# STM32F3x8 register map
File version: 1.2
CPU: CM4 r0p0, little endian, 4 interrupt priority bits
Registers are 32-bit, read-write, reset 0x0 unless marked. A register's access mark holds for its fields unless they carry their own. Offsets are from the block's base; [hi:lo] are bit positions; {n}, {i} and the like mark numbered series; 'fields as' and 'values as' point back to an identical list.

## DBGMCU — Debug support
Base 0xE0042000
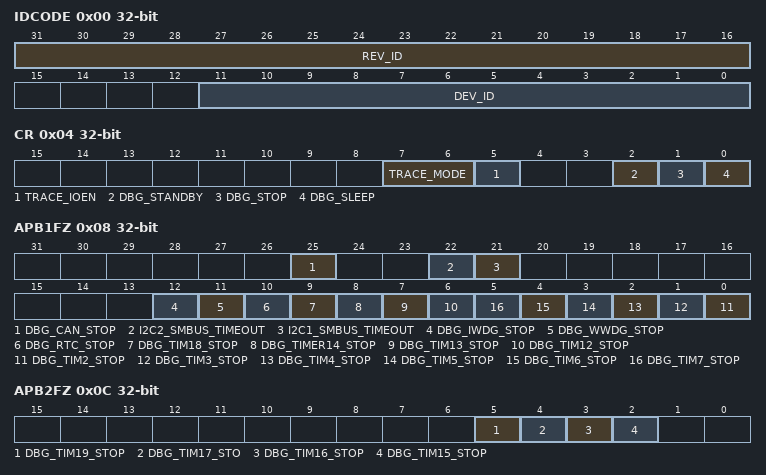
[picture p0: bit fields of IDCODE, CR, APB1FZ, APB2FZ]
0x00 IDCODE ro — MCU Device ID Code Register
  [31:16] REV_ID — Revision Identifier
  [11:0] DEV_ID — Device Identifier
0x04 CR — Debug MCU Configuration Register
  [7:6] TRACE_MODE — Trace pin assignment control
  [5] TRACE_IOEN — Trace pin assignment control
  [2] DBG_STANDBY — Debug Standby Mode
  [1] DBG_STOP — Debug Stop Mode
  [0] DBG_SLEEP — Debug Sleep mode
0x08 APB1FZ — APB Low Freeze Register
  [25] DBG_CAN_STOP — Debug CAN stopped when core is halted
  [22] I2C2_SMBUS_TIMEOUT — SMBUS timeout mode stopped when Core is halted
  [21] I2C1_SMBUS_TIMEOUT — SMBUS timeout mode stopped when Core is halted
  [12] DBG_IWDG_STOP — Debug Independent Wachdog stopped when Core is halted
  [11] DBG_WWDG_STOP — Debug Window Wachdog stopped when Core is halted
  [10] DBG_RTC_STOP — Debug RTC stopped when Core is halted
  [9] DBG_TIM18_STOP — Debug Timer 18 stopped when Core is halted
  [8] DBG_TIMER14_STOP — Debug Timer 14 stopped when Core is halted
  [7] DBG_TIM13_STOP — Debug Timer 13 stopped when Core is halted
  [6] DBG_TIM12_STOP — Debug Timer 12 stopped when Core is halted
  [n-2] DBG_TIM{n}_STOP (n=2..7) — Debug Timer {n} stopped when Core is halted
0x0C APB2FZ — APB High Freeze Register
  [5] DBG_TIM19_STOP — Debug Timer 19 stopped when Core is halted
  [4] DBG_TIM17_STO — Debug Timer 17 stopped when Core is halted
  [3] DBG_TIM16_STOP — Debug Timer 16 stopped when Core is halted
  [2] DBG_TIM15_STOP — Debug Timer 15 stopped when Core is halted

## FMC — Flexible memory controller
Base 0xA0000400
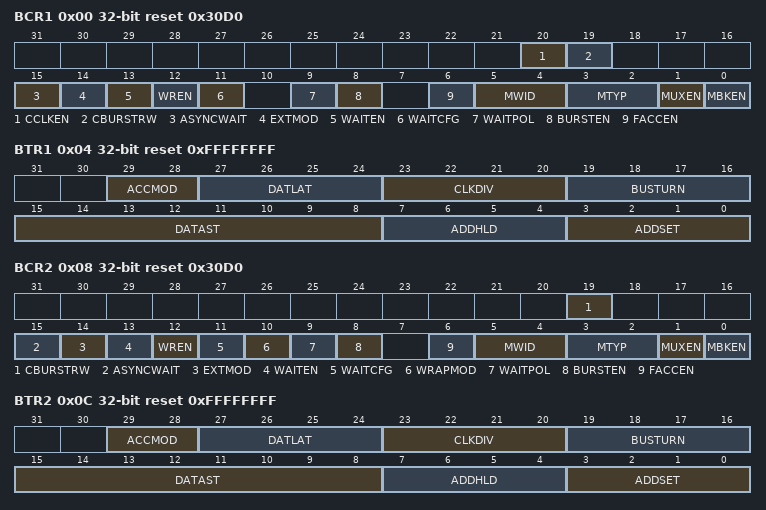
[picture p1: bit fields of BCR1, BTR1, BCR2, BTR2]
0x00 BCR1 reset 0x30D0 — SRAM/NOR-Flash chip-select control register 1
  [20] CCLKEN, [19] CBURSTRW, [15] ASYNCWAIT, [14] EXTMOD, [13] WAITEN, [12] WREN, [11] WAITCFG, [9] WAITPOL, [8] BURSTEN, [6] FACCEN, [5:4] MWID, [3:2] MTYP, [1] MUXEN, [0] MBKEN
0x04 BTR1 reset 0xFFFFFFFF — SRAM/NOR-Flash chip-select timing register 1
  [29:28] ACCMOD, [27:24] DATLAT, [23:20] CLKDIV, [19:16] BUSTURN, [15:8] DATAST, [7:4] ADDHLD, [3:0] ADDSET
0x08 BCR2 reset 0x30D0 — SRAM/NOR-Flash chip-select control register 2
  [19] CBURSTRW, [15] ASYNCWAIT, [14] EXTMOD, [13] WAITEN, [12] WREN, [11] WAITCFG, [10] WRAPMOD, [9] WAITPOL, [8] BURSTEN, [6] FACCEN, [5:4] MWID, [3:2] MTYP, [1] MUXEN, [0] MBKEN
0x0C BTR2 reset 0xFFFFFFFF — SRAM/NOR-Flash chip-select timing register 2
  fields as BTR1
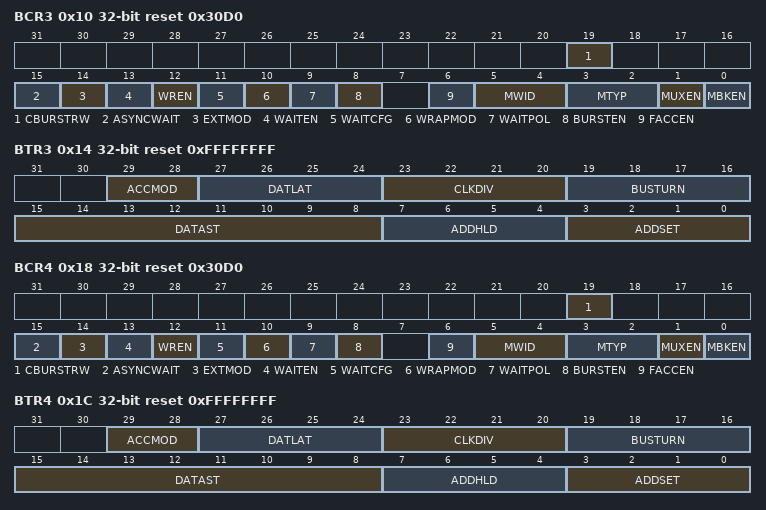
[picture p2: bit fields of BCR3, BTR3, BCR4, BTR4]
0x10 BCR3 reset 0x30D0 — SRAM/NOR-Flash chip-select control register 3
  fields as BCR2
0x14 BTR3 reset 0xFFFFFFFF — SRAM/NOR-Flash chip-select timing register 3
  fields as BTR1
0x18 BCR4 reset 0x30D0 — SRAM/NOR-Flash chip-select control register 4
  fields as BCR2
0x1C BTR4 reset 0xFFFFFFFF — SRAM/NOR-Flash chip-select timing register 4
  fields as BTR1
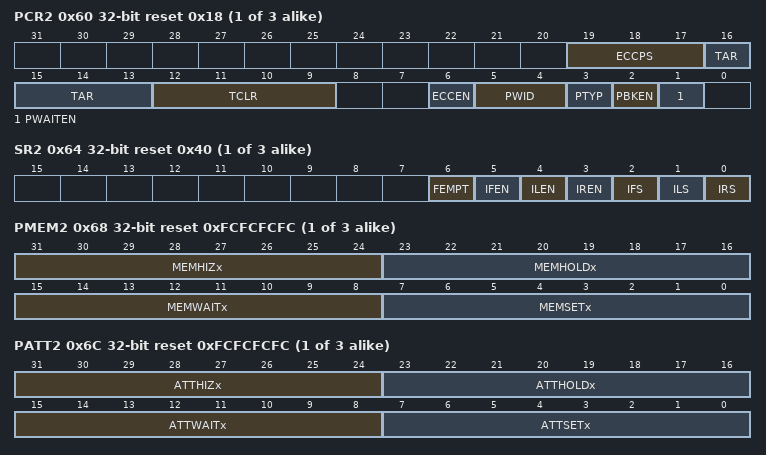
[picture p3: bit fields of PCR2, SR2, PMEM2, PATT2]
{0x20+0x20*i} PCR{i} reset 0x18 (i=2..4) — PC Card/NAND Flash control register {i}
  [19:17] ECCPS, [16:13] TAR, [12:9] TCLR, [6] ECCEN, [5:4] PWID, [3] PTYP, [2] PBKEN, [1] PWAITEN
{0x24+0x20*i} SR{i} access per field reset 0x40 (i=2..4) — FIFO status and interrupt register {i}
  [6] FEMPT ro, [5] IFEN rw, [4] ILEN rw, [3] IREN rw, [2] IFS rw, [1] ILS rw, [0] IRS rw
{0x28+0x20*i} PMEM{i} reset 0xFCFCFCFC (i=2..4) — Common memory space timing register {i}
  [31:24] MEMHIZx, [23:16] MEMHOLDx, [15:8] MEMWAITx, [7:0] MEMSETx
{0x2C+0x20*i} PATT{i} reset 0xFCFCFCFC (i=2..4) — Attribute memory space timing register {i}
  [31:24] ATTHIZx, [23:16] ATTHOLDx, [15:8] ATTWAITx, [7:0] ATTSETx
0x74 ECCR2 ro — ECC result register 2
  [31:0] ECCx
0x94 ECCR3 ro — ECC result register 3
  [31:0] ECCx
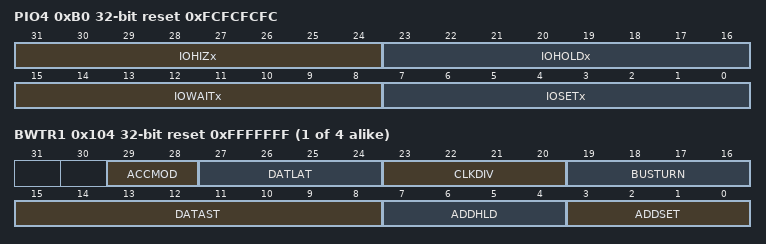
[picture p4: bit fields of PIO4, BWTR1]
0xB0 PIO4 reset 0xFCFCFCFC — I/O space timing register 4
  [31:24] IOHIZx, [23:16] IOHOLDx, [15:8] IOWAITx, [7:0] IOSETx
{0xFC+8i} BWTR{i} reset 0xFFFFFFF (i=1..4) — SRAM/NOR-Flash write timing registers {i}
  [29:28] ACCMOD
  [27:24] DATLAT
  [23:20] CLKDIV
  [19:16] BUSTURN — Bus turnaround phase duration
  [15:8] DATAST
  [7:4] ADDHLD
  [3:0] ADDSET

## ADC2 — Analog-to-Digital Converter
Base 0x50000400
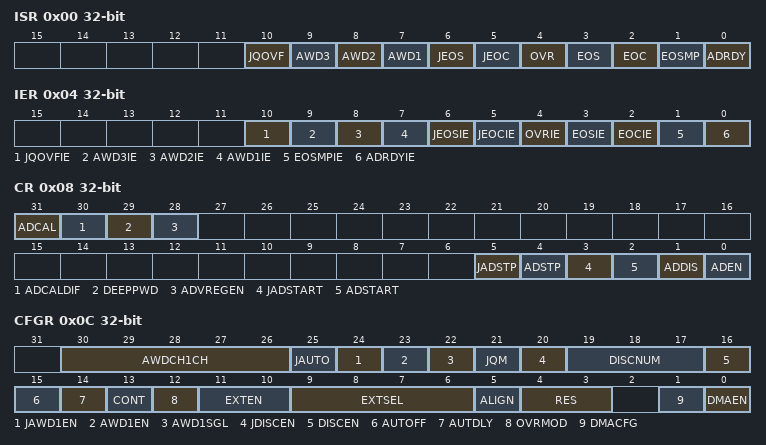
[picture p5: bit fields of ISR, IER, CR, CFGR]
0x00 ISR — interrupt and status register
  [10] JQOVF, [9] AWD3, [8] AWD2, [7] AWD1, [6] JEOS, [5] JEOC, [4] OVR, [3] EOS, [2] EOC, [1] EOSMP, [0] ADRDY
0x04 IER — interrupt enable register
  [10] JQOVFIE, [9] AWD3IE, [8] AWD2IE, [7] AWD1IE, [6] JEOSIE, [5] JEOCIE, [4] OVRIE, [3] EOSIE, [2] EOCIE, [1] EOSMPIE, [0] ADRDYIE
0x08 CR — control register
  [31] ADCAL, [30] ADCALDIF, [29] DEEPPWD, [28] ADVREGEN, [5] JADSTP, [4] ADSTP, [3] JADSTART, [2] ADSTART, [1] ADDIS, [0] ADEN
0x0C CFGR — configuration register
  [30:26] AWDCH1CH, [25] JAUTO, [24] JAWD1EN, [23] AWD1EN, [22] AWD1SGL, [21] JQM, [20] JDISCEN, [19:17] DISCNUM, [16] DISCEN, [15] AUTOFF, [14] AUTDLY, [13] CONT, [12] OVRMOD, [11:10] EXTEN, [9:6] EXTSEL, [5] ALIGN, [4:3] RES, [1] DMACFG, [0] DMAEN
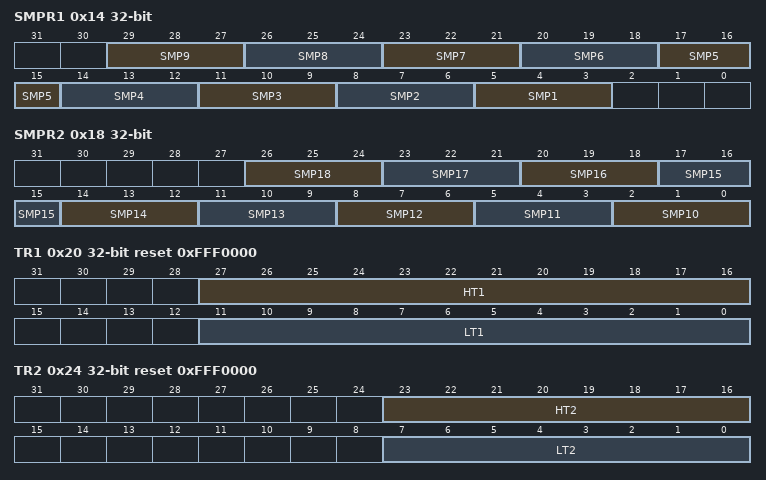
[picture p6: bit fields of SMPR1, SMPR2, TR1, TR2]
0x14 SMPR1 — sample time register 1
  [3n+2:3n] SMP{n} (n=1..9)
0x18 SMPR2 — sample time register 2
  [3n-28:3n-30] SMP{n} (n=10..18)
0x20 TR1 reset 0xFFF0000 — watchdog threshold register 1
  [27:16] HT1, [11:0] LT1
0x24 TR2 reset 0xFFF0000 — watchdog threshold register
  [23:16] HT2, [7:0] LT2
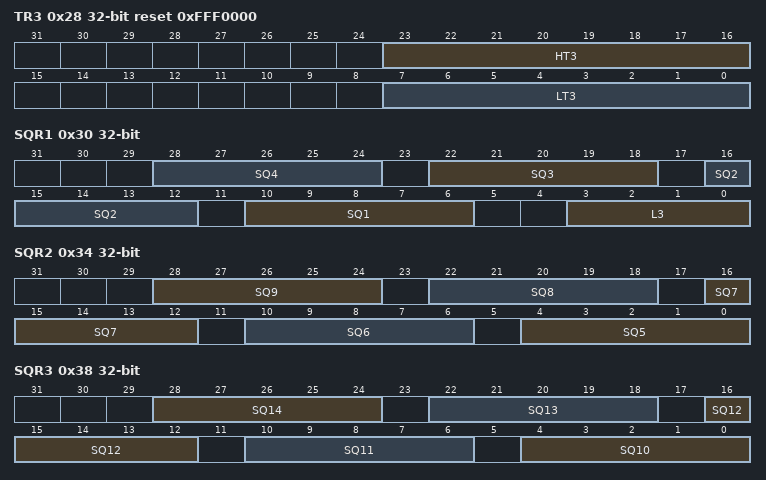
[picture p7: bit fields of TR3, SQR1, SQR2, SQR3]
0x28 TR3 reset 0xFFF0000 — watchdog threshold register 3
  [23:16] HT3, [7:0] LT3
0x30 SQR1 — regular sequence register 1
  [6n+4:6n] SQ{n} (n=1..4), [3:0] L3
0x34 SQR2 — regular sequence register 2
  [6n-26:6n-30] SQ{n} (n=5..9)
0x38 SQR3 — regular sequence register 3
  [6n-56:6n-60] SQ{n} (n=10..14)
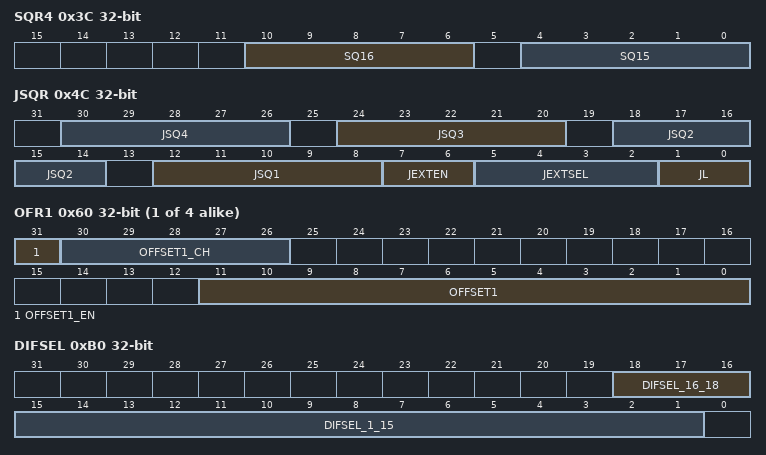
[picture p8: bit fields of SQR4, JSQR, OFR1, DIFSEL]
0x3C SQR4 — regular sequence register 4
  [10:6] SQ16, [4:0] SQ15
0x40 DR ro — regular Data Register
  [15:0] regularDATA
0x4C JSQR — injected sequence register
  [6n+6:6n+2] JSQ{n} (n=1..4), [7:6] JEXTEN, [5:2] JEXTSEL, [1:0] JL
{0x5C+4i} OFR{i} (i=1..4) — offset register {i}
  [31] OFFSET{i}_EN, [30:26] OFFSET{i}_CH, [11:0] OFFSET{i}
{0x7C+4i} JDR{i} ro (i=1..4) — injected data register {i}
  [15:0] JDATA{i}
0xA0 AWD2CR — Analog Watchdog 2 Configuration Register
  [18:1] AWD2CH
0xA4 AWD3CR — Analog Watchdog 3 Configuration Register
  [18:1] AWD3CH
0xB0 DIFSEL access per field — Differential Mode Selection Register 2
  [18:16] DIFSEL_16_18 ro — Differential mode for channels 18 to 16
  [15:1] DIFSEL_1_15 rw — Differential mode for channels 15 to 1
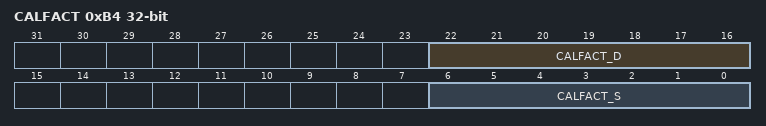
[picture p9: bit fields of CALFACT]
0xB4 CALFACT — Calibration Factors
  [22:16] CALFACT_D, [6:0] CALFACT_S
